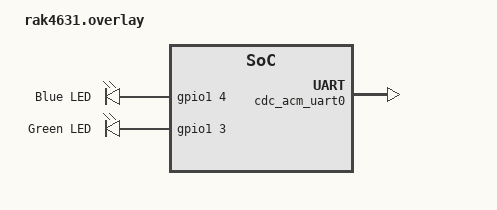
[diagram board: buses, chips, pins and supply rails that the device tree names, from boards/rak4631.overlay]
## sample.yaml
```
sample:
  name: DFU
tests:
  sample.basic.dfu.uart:
    platform_allow:
      - rak3172
      - rak11160
    extra_args: EXTRA_CONF_FILE=overlay_mcuboot.conf
    sysbuild: true
    tags: rak
    build_only: true
  sample.basic.dfu.ble:
    platform_allow:
      - rak3112/esp32s3/procpu
      - rak4631
      - rak5010
      - rak11720
    extra_args: EXTRA_CONF_FILE=overlay_ble.conf;overlay_mcuboot.conf
    sysbuild: true
    tags: rak
    build_only: true
```

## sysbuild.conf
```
# Enable MCUboot bootloader support
SB_CONFIG_BOOTLOADER_MCUBOOT=y
# Do not forget to use your own key at your production code!!!
SB_CONFIG_BOOT_SIGNATURE_KEY_FILE="${APP_DIR}/../../../key/rak_key_ecdsa-p256.pem"
SB_CONFIG_BOOT_SIGNATURE_TYPE_ECDSA_P256=y
```

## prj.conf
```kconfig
CONFIG_MAIN_STACK_SIZE=2048
CONFIG_SYSTEM_WORKQUEUE_STACK_SIZE=2048

CONFIG_LOG=y
CONFIG_LOG_PRINTK=n
# Open following lines to
# use RTT logging for debug!!!
# CONFIG_USE_SEGGER_RTT=y
# CONFIG_LOG_BACKEND_RTT=y
# CONFIG_LOG_BACKEND_UART=n
```

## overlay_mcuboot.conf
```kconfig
CONFIG_MCUMGR=y
CONFIG_NET_BUF=y
CONFIG_ZCBOR=y
CONFIG_CRC=y

# Enable flash operations.
CONFIG_FLASH=y
CONFIG_FLASH_MAP=y
CONFIG_IMG_MANAGER=y
CONFIG_STREAM_FLASH=y

# Enable most core commands.
CONFIG_MCUMGR_GRP_IMG=y
CONFIG_MCUMGR_GRP_OS=y

# Enable the storage erase command.
CONFIG_MCUMGR_GRP_ZBASIC=y
CONFIG_MCUMGR_GRP_ZBASIC_STORAGE_ERASE=y

# Enable the Shell mcumgr transport.
CONFIG_BASE64=y
CONFIG_CRC=y

# Enable the serial MCUmgr transport.
CONFIG_MCUMGR_TRANSPORT_UART=y

# Close BLE related lines for RAK3172 board
# Enable the BT MCUmgr transport.
CONFIG_MCUMGR_TRANSPORT_BT_REASSEMBLY=y
# Enable the Bluetooth mcumgr transport (unauthenticated).
CONFIG_MCUMGR_TRANSPORT_BT=y
CONFIG_MCUMGR_TRANSPORT_BT_CONN_PARAM_CONTROL=y

# Enable the mcumgr Packet Reassembly feature over Bluetooth and its configuration dependencies.
# MCUmgr buffer size is optimized to fit one SMP packet divided into five Bluetooth Write Commands,
# transmitted with the maximum possible MTU value: 498 bytes.
CONFIG_MCUMGR_TRANSPORT_NETBUF_SIZE=2475
CONFIG_MCUMGR_GRP_OS_MCUMGR_PARAMS=y
CONFIG_MCUMGR_TRANSPORT_WORKQUEUE_STACK_SIZE=4608

CONFIG_BOOTLOADER_MCUBOOT=y
```

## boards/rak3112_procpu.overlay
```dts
/ {
	chosen {
		zephyr,console = &usb_serial;
		zephyr,shell-uart = &usb_serial;
		zephyr,uart-mcumgr = &usb_serial;
	};
};
```

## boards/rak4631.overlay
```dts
/ {
	chosen {
		zephyr,console = &cdc_acm_uart0;
		zephyr,uart-mcumgr = &cdc_acm_uart0;
	};

	aliases {
		blue-led = &blue_led;
		green-led = &green_led;
	};

	leds {
		compatible = "gpio-leds";
		blue_led: led_2 {
			gpios = <&gpio1 4 GPIO_ACTIVE_HIGH>;
			label = "Blue LED";
		};
		green_led: led_1 {
			gpios = <&gpio1 3 GPIO_ACTIVE_HIGH>;
			label = "Green LED";
		};
	};
};

&zephyr_udc0 {
	cdc_acm_uart0: cdc_acm_uart0 {
		compatible = "zephyr,cdc-acm-uart";
	};
};
```

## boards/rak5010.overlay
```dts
/ {
	chosen {
		zephyr,console = &cdc_acm_uart0;
		zephyr,uart-mcumgr = &cdc_acm_uart0;
	};

	aliases {
		green-led = &green_led;
	};

	leds {
		compatible = "gpio-leds";
		green_led: led_1 {
			gpios = <&gpio0 12 GPIO_ACTIVE_HIGH>;
			label = "Green LED";
		};
	};
};

&zephyr_udc0 {
	cdc_acm_uart0: cdc_acm_uart0 {
		compatible = "zephyr,cdc-acm-uart";
	};
};
```

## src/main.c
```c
#include <stdio.h>
#include <zephyr/kernel.h>
#include <zephyr/pm/device.h>
#include <zephyr/drivers/gpio.h>
#include <zephyr/drivers/lora.h>

#include "rak_ble_peripheral.h"

#include <zephyr/logging/log.h>
LOG_MODULE_REGISTER(main, LOG_LEVEL_DBG);

int main(void)
{
#if defined(CONFIG_BT_PERIPHERAL)
	int ret = rak_ble_peripheral_init();
	if (ret) {
		LOG_ERR("Failed to init ble peripheral: %d", ret);
	}
#endif

	/* using __TIME__ ensure that a new binary will be built on every
	 * compile which is convenient when testing firmware upgrade.
	 */
	printk("build time: " __DATE__ " " __TIME__ "\n");

	while (1) {
		k_sleep(K_FOREVER);
	}

	return 0;
}
```

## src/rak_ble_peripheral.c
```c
#include <stdio.h>

#include <zephyr/kernel.h>
#include <zephyr/device.h>

#include <zephyr/bluetooth/bluetooth.h>
#include <zephyr/bluetooth/hci.h>
#include <zephyr/bluetooth/conn.h>
#include <zephyr/bluetooth/gatt.h>

#include "rak_ble_peripheral.h"

#include <zephyr/logging/log.h>
LOG_MODULE_REGISTER(ble_peripheral, LOG_LEVEL_INF);

#define DEVICE_NAME     CONFIG_BT_DEVICE_NAME
#define DEVICE_NAME_LEN (sizeof(DEVICE_NAME) - 1)

#define BT_GAP_ADV_FAST_INT_MIN 1600 /* 1000 ms   */
#define BT_GAP_ADV_FAST_INT_MAX 1600 /* 1000 ms   */
/** Connectable advertising with @ref BT_LE_ADV_OPT_CONN */
#define BT_LE_ADV_CUSTOM                                                                           \
	BT_LE_ADV_PARAM(BT_LE_ADV_OPT_CONN, BT_GAP_ADV_FAST_INT_MIN, BT_GAP_ADV_FAST_INT_MAX, NULL)

/* Advertising data */
static const struct bt_data ad[] = {
	BT_DATA_BYTES(BT_DATA_FLAGS, BT_LE_AD_NO_BREDR),
	BT_DATA_BYTES(BT_DATA_SVC_DATA16, 0xaa, 0xfe, /* Eddystone UUID */
		      0x10,                           /* Eddystone-URL frame type */
		      0x00,                           /* Calibrated Tx power at 0m */
		      0x01,                           /* URL Scheme Prefix https://www. */
		      'r', 'a', 'k', 'w', 'i', 'r', 'e', 'l', 'e', 's', 's', 0x07 /* .com */
		      )};

/* Scan response data */
static const struct bt_data sd[] = {BT_DATA(BT_DATA_NAME_COMPLETE, DEVICE_NAME, DEVICE_NAME_LEN)};

static void adv_start_work_handler(struct k_work *work)
{
	bt_le_adv_stop();

	int err = bt_le_adv_start(BT_LE_ADV_CUSTOM, ad, ARRAY_SIZE(ad), sd, ARRAY_SIZE(sd));
	if (err) {
		LOG_ERR("Advertising failed to start (err %d)", err);
		return;
	}

	LOG_INF("Advertising successfully started");
}
K_WORK_DEFINE(adv_start_work, adv_start_work_handler);

static void mtu_updated(struct bt_conn *conn, uint16_t tx, uint16_t rx)
{
	printk("Updated MTU: TX: %d RX: %d bytes\n", tx, rx);
}

static struct bt_gatt_cb gatt_callbacks = {.att_mtu_updated = mtu_updated};

static void connected(struct bt_conn *conn, uint8_t err)
{
	if (err) {
		printk("Connection failed, err 0x%02x %s\n", err, bt_hci_err_to_str(err));
	} else {
		printk("Connected\n");
	}
}

static void disconnected(struct bt_conn *conn, uint8_t reason)
{
	printk("Disconnected, reason 0x%02x %s\n", reason, bt_hci_err_to_str(reason));
	k_work_submit(&adv_start_work);
}

BT_CONN_CB_DEFINE(conn_callbacks) = {
	.connected = connected,
	.disconnected = disconnected,
};

static void bt_ready_handler(int err)
{
	if (err) {
		LOG_ERR("Ble peripheral init failed (err %d)", err);
		return;
	}

	bt_gatt_cb_register(&gatt_callbacks);
	k_work_submit(&adv_start_work);
}

int rak_ble_peripheral_init(void)
{
	int err = bt_enable(bt_ready_handler);
	if (err) {
		LOG_ERR("Bluetooth init failed (err %d)", err);
		return err;
	}

	return err;
}
```
